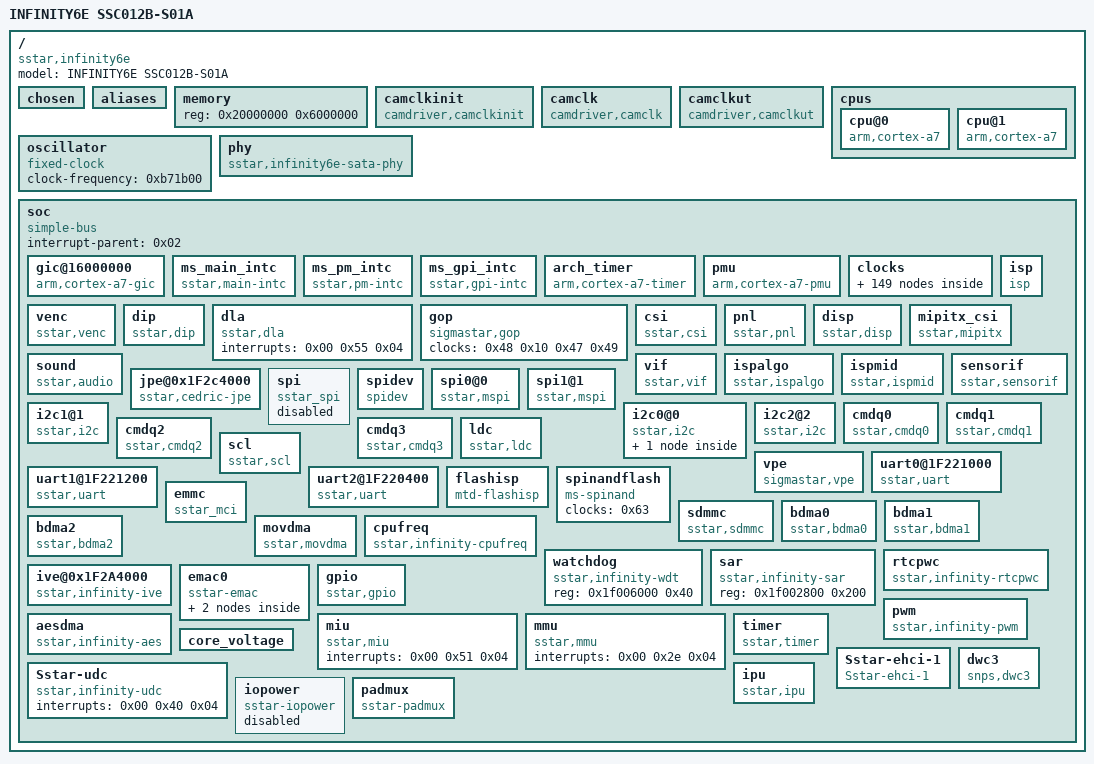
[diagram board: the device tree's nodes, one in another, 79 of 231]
/dts-v1/;

/ {
	#address-cells = <0x01>;
	#size-cells = <0x01>;
	model = "INFINITY6E SSC012B-S01A";
	compatible = "sstar,infinity6e";

	chosen {
		bootargs = "console=ttyS0,38400n8r androidboot.console=ttyS0 root=/dev/mtdblock0 init=/linuxrc LX_MEM=0x3ee0000 mma_heap=mma_heap_name0,miu=0,sz=0x2000000 mma_memblock_remove=1";
	};

	aliases {
		console = "/soc/uart0@1F221000";
		serial0 = "/soc/uart0@1F221000";
		serial1 = "/soc/uart1@1F221200";
		serial2 = "/soc/uart2@1F220400";
	};

	memory {
		device_type = "memory";
		reg = <0x20000000 0x6000000>;
	};

	camclkinit {
		compatible = "camdriver,camclkinit";
		status = "ok";
	};

	camclk {
		compatible = "camdriver,camclk";
		status = "ok";
	};

	camclkut {
		compatible = "camdriver,camclkut";
		status = "ok";
	};

	cpus {
		#address-cells = <0x01>;
		#size-cells = <0x00>;

		cpu@0 {
			device_type = "cpu";
			compatible = "arm,cortex-a7";
			clock-frequency = <0x3b9aca00>;
			clocks = <0x01>;
			reg = <0x00>;
			operating-points = <0x124f80 0xf4240 0x10c8e0 0xf4240 0xf4240 0xdbba0 0xdbba0 0xdbba0 0xc3500 0xcf850 0x927c0 0xcf850 0x61a80 0xcf850>;
		};

		cpu@1 {
			device_type = "cpu";
			compatible = "arm,cortex-a7";
			clock-frequency = <0x3b9aca00>;
			clocks = <0x01>;
			reg = <0x01>;
		};
	};

	oscillator {
		compatible = "fixed-clock";
		#clock-cells = <0x00>;
		clock-frequency = <0xb71b00>;
	};

	phy {
		compatible = "sstar,infinity6e-sata-phy";
		io_phy_addr = <0x1f000000>;
		banks = <0x1523 0x1524 0x1525>;
		reg = <0x1f2a4600 0x300>;
		#phy-cells = <0x00>;
		phy_type = "utmi";
		status = "ok";
		linux,phandle = <0x71>;
		phandle = <0x71>;
	};

	soc {
		compatible = "simple-bus";
		interrupt-parent = <0x02>;
		#address-cells = <0x01>;
		#size-cells = <0x01>;
		ranges;

		gic@16000000 {
			compatible = "arm,cortex-a7-gic";
			#interrupt-cells = <0x03>;
			#address-cells = <0x01>;
			#size-cells = <0x01>;
			interrupt-controller;
			interrupt-parent = <0x03>;
			reg = <0x16001000 0x1000 0x16002000 0x1000>;
			linux,phandle = <0x03>;
			phandle = <0x03>;
		};

		ms_main_intc {
			compatible = "sstar,main-intc";
			#interrupt-cells = <0x03>;
			#address-cells = <0x01>;
			#size-cells = <0x01>;
			interrupt-parent = <0x03>;
			interrupt-controller;
			linux,phandle = <0x02>;
			phandle = <0x02>;
		};

		ms_pm_intc {
			compatible = "sstar,pm-intc";
			#interrupt-cells = <0x01>;
			interrupt-parent = <0x02>;
			interrupt-controller;
			interrupts = <0x00 0x22 0x04>;
		};

		ms_gpi_intc {
			compatible = "sstar,gpi-intc";
			#interrupt-cells = <0x01>;
			interrupt-parent = <0x02>;
			interrupt-controller;
			interrupts = <0x00 0x58 0x04>;
			linux,phandle = <0x5d>;
			phandle = <0x5d>;
		};

		arch_timer {
			compatible = "arm,cortex-a7-timer\0arm,armv7-timer";
			interrupt-parent = <0x03>;
			interrupts = <0x01 0x0d 0x308 0x01 0x0e 0x308 0x01 0x0b 0x308 0x01 0x0a 0x308>;
			clock-frequency = <0x5b8d80>;
			always-on;
		};

		pmu {
			compatible = "arm,cortex-a7-pmu";
			interrupt-parent = <0x03>;
			interrupts = <0x00 0x0a 0x04 0x00 0x10 0x04 0x00 0x16 0x04 0x00 0x1c 0x04>;
		};

		clocks {
			#address-cells = <0x01>;
			#size-cells = <0x01>;
			ranges;

			CLK_VOID {
				#clock-cells = <0x00>;
				compatible = "fixed-clock";
				clock-frequency = <0x01>;
				linux,phandle = <0x17>;
				phandle = <0x17>;
			};

			CLK_utmi_480m {
				#clock-cells = <0x00>;
				compatible = "fixed-clock";
				clock-frequency = <0x1c9c3800>;
				linux,phandle = <0x35>;
				phandle = <0x35>;
			};

			CLK_mpll_432m {
				#clock-cells = <0x00>;
				compatible = "fixed-clock";
				clock-frequency = <0x19bfcc00>;
				linux,phandle = <0x14>;
				phandle = <0x14>;
			};

			CLK_upll_384m {
				#clock-cells = <0x00>;
				compatible = "fixed-clock";
				clock-frequency = <0x16e36000>;
				linux,phandle = <0x15>;
				phandle = <0x15>;
			};

			CLK_mpll_345m {
				#clock-cells = <0x00>;
				compatible = "fixed-clock";
				clock-frequency = <0x14904840>;
				linux,phandle = <0x3e>;
				phandle = <0x3e>;
			};

			CLK_upll_320m {
				#clock-cells = <0x00>;
				compatible = "fixed-clock";
				clock-frequency = <0x1312d000>;
				linux,phandle = <0x36>;
				phandle = <0x36>;
			};

			CLK_mpll_288m {
				#clock-cells = <0x00>;
				compatible = "fixed-clock";
				clock-frequency = <0x112a8800>;
				linux,phandle = <0x04>;
				phandle = <0x04>;
			};

			CLK_utmi_240m {
				#clock-cells = <0x00>;
				compatible = "fixed-clock";
				clock-frequency = <0xe4e1c00>;
				linux,phandle = <0x37>;
				phandle = <0x37>;
			};

			CLK_mpll_216m {
				#clock-cells = <0x00>;
				compatible = "fixed-clock";
				clock-frequency = <0xcdfe600>;
				linux,phandle = <0x05>;
				phandle = <0x05>;
			};

			CLK_utmi_192m {
				#clock-cells = <0x00>;
				compatible = "fixed-clock";
				clock-frequency = <0xb71b000>;
				linux,phandle = <0x08>;
				phandle = <0x08>;
			};

			CLK_mpll_172m {
				#clock-cells = <0x00>;
				compatible = "fixed-clock";
				clock-frequency = <0xa4cb800>;
				linux,phandle = <0x26>;
				phandle = <0x26>;
			};

			CLK_utmi_160m {
				#clock-cells = <0x00>;
				compatible = "fixed-clock";
				clock-frequency = <0x9896800>;
				linux,phandle = <0x09>;
				phandle = <0x09>;
			};

			CLK_mpll_123m {
				#clock-cells = <0x00>;
				compatible = "fixed-clock";
				clock-frequency = <0x75aef40>;
				linux,phandle = <0x06>;
				phandle = <0x06>;
			};

			CLK_mpll_86m {
				#clock-cells = <0x00>;
				compatible = "fixed-clock";
				clock-frequency = <0x5265c00>;
				linux,phandle = <0x07>;
				phandle = <0x07>;
			};

			CLK_mpll_288m_div2 {
				#clock-cells = <0x00>;
				compatible = "fixed-factor-clock";
				clocks = <0x04>;
				clock-div = <0x02>;
				clock-mult = <0x01>;
				linux,phandle = <0x27>;
				phandle = <0x27>;
			};

			CLK_mpll_288m_div4 {
				#clock-cells = <0x00>;
				compatible = "fixed-factor-clock";
				clocks = <0x04>;
				clock-div = <0x04>;
				clock-mult = <0x01>;
				linux,phandle = <0x23>;
				phandle = <0x23>;
			};

			CLK_mpll_288m_div8 {
				#clock-cells = <0x00>;
				compatible = "fixed-factor-clock";
				clocks = <0x04>;
				clock-div = <0x08>;
				clock-mult = <0x01>;
				linux,phandle = <0x20>;
				phandle = <0x20>;
			};

			CLK_mpll_216m_div2 {
				#clock-cells = <0x00>;
				compatible = "fixed-factor-clock";
				clocks = <0x05>;
				clock-div = <0x02>;
				clock-mult = <0x01>;
				linux,phandle = <0x1c>;
				phandle = <0x1c>;
			};

			CLK_mpll_216m_div4 {
				#clock-cells = <0x00>;
				compatible = "fixed-factor-clock";
				clocks = <0x05>;
				clock-div = <0x04>;
				clock-mult = <0x01>;
				linux,phandle = <0x22>;
				phandle = <0x22>;
			};

			CLK_mpll_216m_div8 {
				#clock-cells = <0x00>;
				compatible = "fixed-factor-clock";
				clocks = <0x05>;
				clock-div = <0x08>;
				clock-mult = <0x01>;
				linux,phandle = <0x1f>;
				phandle = <0x1f>;
			};

			CLK_mpll_123m_div2 {
				#clock-cells = <0x00>;
				compatible = "fixed-factor-clock";
				clocks = <0x06>;
				clock-div = <0x02>;
				clock-mult = <0x01>;
				linux,phandle = <0x2b>;
				phandle = <0x2b>;
			};

			CLK_mpll_86m_div2 {
				#clock-cells = <0x00>;
				compatible = "fixed-factor-clock";
				clocks = <0x07>;
				clock-div = <0x02>;
				clock-mult = <0x01>;
				linux,phandle = <0x2d>;
				phandle = <0x2d>;
			};

			CLK_mpll_86m_div4 {
				#clock-cells = <0x00>;
				compatible = "fixed-factor-clock";
				clocks = <0x07>;
				clock-div = <0x04>;
				clock-mult = <0x01>;
				linux,phandle = <0x2e>;
				phandle = <0x2e>;
			};

			CLK_mpll_86m_div16 {
				#clock-cells = <0x00>;
				compatible = "fixed-factor-clock";
				clocks = <0x07>;
				clock-div = <0x10>;
				clock-mult = <0x01>;
				linux,phandle = <0x2f>;
				phandle = <0x2f>;
			};

			CLK_utmi_192m_div4 {
				#clock-cells = <0x00>;
				compatible = "fixed-factor-clock";
				clocks = <0x08>;
				clock-div = <0x04>;
				clock-mult = <0x01>;
				linux,phandle = <0x2c>;
				phandle = <0x2c>;
			};

			CLK_utmi_160m_div4 {
				#clock-cells = <0x00>;
				compatible = "fixed-factor-clock";
				clocks = <0x09>;
				clock-div = <0x04>;
				clock-mult = <0x01>;
				linux,phandle = <0x38>;
				phandle = <0x38>;
			};

			CLK_utmi_160m_div5 {
				#clock-cells = <0x00>;
				compatible = "fixed-factor-clock";
				clocks = <0x09>;
				clock-div = <0x05>;
				clock-mult = <0x01>;
				linux,phandle = <0x3b>;
				phandle = <0x3b>;
			};

			CLK_utmi_160m_div8 {
				#clock-cells = <0x00>;
				compatible = "fixed-factor-clock";
				clocks = <0x09>;
				clock-div = <0x08>;
				clock-mult = <0x01>;
				linux,phandle = <0x3c>;
				phandle = <0x3c>;
			};

			CLK_xtali_12m {
				#clock-cells = <0x00>;
				compatible = "fixed-clock";
				clock-frequency = <0xb71b00>;
				linux,phandle = <0x0a>;
				phandle = <0x0a>;
			};

			CLK_xtali_12m_div2 {
				#clock-cells = <0x00>;
				compatible = "fixed-factor-clock";
				clocks = <0x0a>;
				clock-div = <0x02>;
				clock-mult = <0x01>;
				linux,phandle = <0x24>;
				phandle = <0x24>;
			};

			CLK_xtali_12m_div4 {
				#clock-cells = <0x00>;
				compatible = "fixed-factor-clock";
				clocks = <0x0a>;
				clock-div = <0x04>;
				clock-mult = <0x01>;
				linux,phandle = <0x25>;
				phandle = <0x25>;
			};

			CLK_xtali_12m_div8 {
				#clock-cells = <0x00>;
				compatible = "fixed-factor-clock";
				clocks = <0x0a>;
				clock-div = <0x08>;
				clock-mult = <0x01>;
				linux,phandle = <0x18>;
				phandle = <0x18>;
			};

			CLK_xtali_12m_div16 {
				#clock-cells = <0x00>;
				compatible = "fixed-factor-clock";
				clocks = <0x0a>;
				clock-div = <0x10>;
				clock-mult = <0x01>;
				linux,phandle = <0x19>;
				phandle = <0x19>;
			};

			CLK_xtali_12m_div40 {
				#clock-cells = <0x00>;
				compatible = "fixed-factor-clock";
				clocks = <0x0a>;
				clock-div = <0x28>;
				clock-mult = <0x01>;
				linux,phandle = <0x3d>;
				phandle = <0x3d>;
			};

			CLK_xtali_12m_div64 {
				#clock-cells = <0x00>;
				compatible = "fixed-factor-clock";
				clocks = <0x0a>;
				clock-div = <0x40>;
				clock-mult = <0x01>;
				linux,phandle = <0x1a>;
				phandle = <0x1a>;
			};

			CLK_xtali_12m_div128 {
				#clock-cells = <0x00>;
				compatible = "fixed-factor-clock";
				clocks = <0x0a>;
				clock-div = <0x80>;
				clock-mult = <0x01>;
				linux,phandle = <0x1b>;
				phandle = <0x1b>;
			};

			CLK_xtali_24m {
				#clock-cells = <0x00>;
				compatible = "fixed-clock";
				clock-frequency = <0x16e3600>;
				linux,phandle = <0x0b>;
				phandle = <0x0b>;
			};

			CLK_RTC_CLK_32K {
				#clock-cells = <0x00>;
				compatible = "fixed-clock";
				clock-frequency = <0x7d00>;
			};

			CLK_pm_riu_w_clk_in {
				#clock-cells = <0x00>;
				compatible = "fixed-clock";
				clock-frequency = <0x66ff300>;
			};

			CLK_miupll_clk {
				#clock-cells = <0x00>;
				compatible = "fixed-clock";
				clock-frequency = <0x17d78400>;
				linux,phandle = <0x16>;
				phandle = <0x16>;
			};

			CLK_ddrpll_clk {
				#clock-cells = <0x00>;
				compatible = "fixed-clock";
				clock-frequency = <0x7f22ff40>;
			};

			CLK_lpll_clk {
				#clock-cells = <0x00>;
				compatible = "fixed-clock";
				clock-frequency = <0x5f5e100>;
				linux,phandle = <0x30>;
				phandle = <0x30>;
			};

			CLK_ven_pll {
				#clock-cells = <0x00>;
				compatible = "sstar,complex-clock";
				clocks = <0x0b>;
				linux,phandle = <0x39>;
				phandle = <0x39>;
			};

			CLK_ven_pll_div6 {
				#clock-cells = <0x00>;
				compatible = "fixed-clock";
				clock-frequency = <0x632ea00>;
				linux,phandle = <0x21>;
				phandle = <0x21>;
			};

			CLK_lpll_div2 {
				#clock-cells = <0x00>;
				compatible = "fixed-clock";
				clock-frequency = <0x2faf080>;
				linux,phandle = <0x31>;
				phandle = <0x31>;
			};

			CLK_lpll_div4 {
				#clock-cells = <0x00>;
				compatible = "fixed-clock";
				clock-frequency = <0x17d7840>;
				linux,phandle = <0x32>;
				phandle = <0x32>;
			};

			CLK_lpll_div8 {
				#clock-cells = <0x00>;
				compatible = "fixed-clock";
				clock-frequency = <0xbebc20>;
				linux,phandle = <0x33>;
				phandle = <0x33>;
			};

			CLK_armpll_37p125m {
				#clock-cells = <0x00>;
				compatible = "fixed-clock";
				clock-frequency = <0x23c3460>;
				linux,phandle = <0x34>;
				phandle = <0x34>;
			};

			CLK_riu_w_clk_in {
				#clock-cells = <0x00>;
				compatible = "fixed-factor-clock";
				clocks = <0x0c>;
				clock-div = <0x01>;
				clock-mult = <0x01>;
			};

			CLK_riu_w_clk_top {
				#clock-cells = <0x00>;
				compatible = "fixed-factor-clock";
				clocks = <0x0c>;
				clock-div = <0x01>;
				clock-mult = <0x01>;
			};

			CLK_riu_w_clk_sc_gp {
				#clock-cells = <0x00>;
				compatible = "fixed-factor-clock";
				clocks = <0x0c>;
				clock-div = <0x01>;
				clock-mult = <0x01>;
			};

			CLK_riu_w_clk_vhe_gp {
				#clock-cells = <0x00>;
				compatible = "fixed-factor-clock";
				clocks = <0x0c>;
				clock-div = <0x01>;
				clock-mult = <0x01>;
			};

			CLK_riu_w_clk_hemcu_gp {
				#clock-cells = <0x00>;
				compatible = "fixed-factor-clock";
				clocks = <0x0c>;
				clock-div = <0x01>;
				clock-mult = <0x01>;
			};

			CLK_riu_w_clk_mipi_if_gp {
				#clock-cells = <0x00>;
				compatible = "fixed-factor-clock";
				clocks = <0x0c>;
				clock-div = <0x01>;
				clock-mult = <0x01>;
			};

			CLK_riu_w_clk_mcu_if_gp {
				#clock-cells = <0x00>;
				compatible = "fixed-factor-clock";
				clocks = <0x0c>;
				clock-div = <0x01>;
				clock-mult = <0x01>;
			};

			CLK_fuart0_synth_out {
				#clock-cells = <0x00>;
				compatible = "fixed-clock";
				clock-frequency = <0x19bfcc00>;
				linux,phandle = <0x28>;
				phandle = <0x28>;
			};

			CLK_miu_p {
				#clock-cells = <0x00>;
				compatible = "fixed-factor-clock";
				clocks = <0x0d>;
				clock-div = <0x01>;
				clock-mult = <0x01>;
				linux,phandle = <0x1e>;
				phandle = <0x1e>;
			};

			CLK_mspi0_p {
				#clock-cells = <0x00>;
				compatible = "fixed-factor-clock";
				clocks = <0x0e>;
				clock-div = <0x01>;
				clock-mult = <0x01>;
				linux,phandle = <0x29>;
				phandle = <0x29>;
			};

			CLK_mspi1_p {
				#clock-cells = <0x00>;
				compatible = "fixed-factor-clock";
				clocks = <0x0f>;
				clock-div = <0x01>;
				clock-mult = <0x01>;
				linux,phandle = <0x2a>;
				phandle = <0x2a>;
			};

			CLK_miu_vhe_gp_p {
				#clock-cells = <0x00>;
				compatible = "fixed-factor-clock";
				clocks = <0x0d>;
				clock-div = <0x01>;
				clock-mult = <0x01>;
			};

			CLK_miu_sc_gp_p {
				#clock-cells = <0x00>;
				compatible = "fixed-factor-clock";
				clocks = <0x0d>;
				clock-div = <0x01>;
				clock-mult = <0x01>;
			};

			CLK_mcu_p {
				#clock-cells = <0x00>;
				compatible = "fixed-factor-clock";
				clocks = <0x0c>;
				clock-div = <0x01>;
				clock-mult = <0x01>;
				linux,phandle = <0x1d>;
				phandle = <0x1d>;
			};

			CLK_fclk1_p {
				#clock-cells = <0x00>;
				compatible = "fixed-factor-clock";
				clocks = <0x10>;
				clock-div = <0x01>;
				clock-mult = <0x01>;
				linux,phandle = <0x12>;
				phandle = <0x12>;
			};

			CLK_sdio_p {
				#clock-cells = <0x00>;
				compatible = "fixed-factor-clock";
				clocks = <0x11>;
				clock-div = <0x01>;
				clock-mult = <0x01>;
			};

			CLK_tck_buf {
				#clock-cells = <0x00>;
				compatible = "fixed-clock";
				clock-frequency = <0x2faf080>;
			};

			CLK_eth_buf {
				#clock-cells = <0x00>;
				compatible = "fixed-clock";
				clock-frequency = <0x7735940>;
				linux,phandle = <0x3f>;
				phandle = <0x3f>;
			};

			CLK_rmii_buf {
				#clock-cells = <0x00>;
				compatible = "fixed-clock";
				clock-frequency = <0x7735940>;
				linux,phandle = <0x40>;
				phandle = <0x40>;
			};

			CLK_emac_testrx125_in_lan {
				#clock-cells = <0x00>;
				compatible = "fixed-clock";
				clock-frequency = <0x7735940>;
				linux,phandle = <0x3a>;
				phandle = <0x3a>;
			};

			CLK_gop0 {
				#clock-cells = <0x00>;
				compatible = "fixed-factor-clock";
				clocks = <0x12>;
				clock-div = <0x01>;
				clock-mult = <0x01>;
				linux,phandle = <0x48>;
				phandle = <0x48>;
			};

			CLK_rtc_32k {
				#clock-cells = <0x00>;
				compatible = "fixed-clock";
				clock-frequency = <0x8000>;
				linux,phandle = <0x41>;
				phandle = <0x41>;
			};

			CLK_fro {
				#clock-cells = <0x00>;
				compatible = "fixed-clock";
				clock-frequency = <0x2dc6c00>;
				linux,phandle = <0x13>;
				phandle = <0x13>;
			};

			CLK_fro_div2 {
				#clock-cells = <0x00>;
				compatible = "fixed-factor-clock";
				clocks = <0x13>;
				clock-div = <0x02>;
				clock-mult = <0x01>;
				linux,phandle = <0x43>;
				phandle = <0x43>;
			};

			CLK_fro_div8 {
				#clock-cells = <0x00>;
				compatible = "fixed-factor-clock";
				clocks = <0x13>;
				clock-div = <0x08>;
				clock-mult = <0x01>;
				linux,phandle = <0x42>;
				phandle = <0x42>;
			};

			CLK_fro_div16 {
				#clock-cells = <0x00>;
				compatible = "fixed-factor-clock";
				clocks = <0x13>;
				clock-div = <0x10>;
				clock-mult = <0x01>;
				linux,phandle = <0x44>;
				phandle = <0x44>;
			};

			CLK_cpupll_clk {
				#clock-cells = <0x00>;
				compatible = "sstar,complex-clock";
				clocks = <0x14>;
				linux,phandle = <0x01>;
				phandle = <0x01>;
			};

			CLK_utmi {
				#clock-cells = <0x00>;
				compatible = "fixed-clock";
				clock-frequency = <0x1c9c3800>;
				linux,phandle = <0x70>;
				phandle = <0x70>;
			};

			CLK_bach {
				#clock-cells = <0x00>;
				compatible = "sstar,composite-clock";
				clocks = <0x15>;
				reg = <0x1f2071b4 0x04>;
				gate-shift = <0x07>;
				linux,phandle = <0x56>;
				phandle = <0x56>;
			};

			CLK_miu {
				#clock-cells = <0x00>;
				compatible = "sstar,composite-clock";
				clocks = <0x05 0x16 0x17 0x17>;
				reg = <0x1f20705c 0x04>;
				mux-shift = <0x02>;
				mux-width = <0x02>;
				gate-shift = <0x00>;
				glitch-shift = <0x04>;
				auto-enable = <0x01>;
				linux,phandle = <0x0d>;
				phandle = <0x0d>;
			};

			CLK_miu_boot {
				#clock-cells = <0x00>;
				compatible = "sstar,composite-clock";
				clocks = <0x0a 0x0d>;
				reg = <0x1f20705c 0x04>;
				mux-shift = <0x02>;
				mux-width = <0x01>;
				gate-shift = <0x00>;
				auto-enable = <0x01>;
			};

			CLK_ddr_syn {
				#clock-cells = <0x00>;
				compatible = "sstar,composite-clock";
				clocks = <0x14 0x05 0x0a 0x17>;
				reg = <0x1f207064 0x04>;
				mux-shift = <0x02>;
				mux-width = <0x02>;
				gate-shift = <0x00>;
				auto-enable = <0x01>;
			};

			CLK_miu_rec {
				#clock-cells = <0x00>;
				compatible = "sstar,composite-clock";
				clocks = <0x18 0x19 0x1a 0x1b>;
				reg = <0x1f207060 0x04>;
				mux-shift = <0x02>;
				mux-width = <0x02>;
				gate-shift = <0x00>;
				auto-enable = <0x01>;
			};

			CLK_mcu {
				#clock-cells = <0x00>;
				compatible = "sstar,composite-clock";
				clocks = <0x05 0x14 0x15 0x1c>;
				reg = <0x1f207004 0x04>;
				mux-shift = <0x02>;
				mux-width = <0x02>;
				gate-shift = <0x00>;
				glitch-shift = <0x04>;
				auto-enable = <0x01>;
				linux,phandle = <0x0c>;
				phandle = <0x0c>;
			};

			CLK_riubrdg {
				#clock-cells = <0x00>;
				compatible = "sstar,composite-clock";
				clocks = <0x1d 0x17 0x17 0x17>;
				reg = <0x1f207004 0x04>;
				mux-shift = <0x0a>;
				mux-width = <0x02>;
				gate-shift = <0x08>;
				auto-enable = <0x01>;
			};

			CLK_bdma {
				#clock-cells = <0x00>;
				compatible = "sstar,composite-clock";
				clocks = <0x1e 0x17 0x17 0x17>;
				reg = <0x1f207180 0x04>;
				mux-shift = <0x02>;
				mux-width = <0x02>;
				gate-shift = <0x00>;
				auto-enable = <0x00>;
				linux,phandle = <0x63>;
				phandle = <0x63>;
			};

			CLK_spi_arb {
				#clock-cells = <0x00>;
				compatible = "sstar,composite-clock";
				clocks = <0x05 0x1c 0x07 0x1e>;
				reg = <0x1f2070c8 0x04>;
				mux-shift = <0x02>;
				mux-width = <0x02>;
				gate-shift = <0x00>;
				glitch-shift = <0x04>;
				auto-enable = <0x01>;
			};

			CLK_spi_flash {
				#clock-cells = <0x00>;
				compatible = "sstar,composite-clock";
				clocks = <0x0a 0x1f 0x20 0x21 0x22 0x23 0x07 0x1c>;
				reg = <0x1f2070e0 0x04>;
				mux-shift = <0x02>;
				mux-width = <0x03>;
				gate-shift = <0x00>;
				glitch-shift = <0x05>;
				auto-enable = <0x01>;
			};

			CLK_pwm {
				#clock-cells = <0x00>;
				compatible = "sstar,composite-clock";
				clocks = <0x0a 0x24 0x25 0x18 0x0b 0x07 0x17 0x17>;
				reg = <0x1f2070e0 0x04>;
				mux-shift = <0x0a>;
				mux-width = <0x03>;
				gate-shift = <0x08>;
				auto-enable = <0x00>;
				linux,phandle = <0x6e>;
				phandle = <0x6e>;
			};

			CLK_uart0 {
				#clock-cells = <0x00>;
				compatible = "sstar,composite-clock";
				clocks = <0x26 0x27 0x0a 0x17>;
				reg = <0x1f2070c4 0x04>;
				mux-shift = <0x02>;
				mux-width = <0x02>;
				gate-shift = <0x00>;
				auto-enable = <0x00>;
				linux,phandle = <0x60>;
				phandle = <0x60>;
			};

			CLK_uart1 {
				#clock-cells = <0x00>;
				compatible = "sstar,composite-clock";
				clocks = <0x26 0x27 0x0a 0x17>;
				reg = <0x1f2070c4 0x04>;
				mux-shift = <0x0a>;
				mux-width = <0x02>;
				gate-shift = <0x08>;
				auto-enable = <0x00>;
				linux,phandle = <0x61>;
				phandle = <0x61>;
			};

			CLK_fuart0_synth_in {
				#clock-cells = <0x00>;
				compatible = "sstar,composite-clock";
				clocks = <0x14 0x05 0x17 0x17>;
				reg = <0x1f2070d0 0x04>;
				mux-shift = <0x06>;
				mux-width = <0x02>;
				gate-shift = <0x04>;
				auto-enable = <0x00>;
			};

			CLK_fuart {
				#clock-cells = <0x00>;
				compatible = "sstar,composite-clock";
				clocks = <0x26 0x27 0x0a 0x28>;
				reg = <0x1f2070d0 0x04>;
				mux-shift = <0x02>;
				mux-width = <0x02>;
				gate-shift = <0x00>;
				auto-enable = <0x00>;
				linux,phandle = <0x62>;
				phandle = <0x62>;
			};

			CLK_mspi0 {
				#clock-cells = <0x00>;
				compatible = "sstar,composite-clock";
				clocks = <0x1c 0x22 0x0a 0x27>;
				reg = <0x1f2070cc 0x04>;
				mux-shift = <0x02>;
				mux-width = <0x02>;
				gate-shift = <0x00>;
				auto-enable = <0x00>;
				linux,phandle = <0x0e>;
				phandle = <0x0e>;
			};

			CLK_mspi1 {
				#clock-cells = <0x00>;
				compatible = "sstar,composite-clock";
				clocks = <0x1c 0x22 0x0a 0x27>;
				reg = <0x1f2070cc 0x04>;
				mux-shift = <0x0a>;
				mux-width = <0x02>;
				gate-shift = <0x08>;
				auto-enable = <0x00>;
				linux,phandle = <0x0f>;
				phandle = <0x0f>;
			};

			CLK_mspi {
				#clock-cells = <0x00>;
				compatible = "sstar,composite-clock";
				clocks = <0x29 0x2a>;
				reg = <0x1f2070cc 0x04>;
				mux-shift = <0x0e>;
				mux-width = <0x01>;
				gate-shift = <0x0c>;
				auto-enable = <0x00>;
				linux,phandle = <0x5b>;
				phandle = <0x5b>;
			};

			CLK_miic0 {
				#clock-cells = <0x00>;
				compatible = "sstar,composite-clock";
				clocks = <0x23 0x22 0x0a 0x17>;
				reg = <0x1f2070dc 0x04>;
				mux-shift = <0x02>;
				mux-width = <0x02>;
				gate-shift = <0x00>;
				auto-enable = <0x00>;
				linux,phandle = <0x5c>;
				phandle = <0x5c>;
			};

			CLK_miic1 {
				#clock-cells = <0x00>;
				compatible = "sstar,composite-clock";
				clocks = <0x23 0x22 0x0a 0x17>;
				reg = <0x1f2070dc 0x04>;
				mux-shift = <0x0a>;
				mux-width = <0x02>;
				gate-shift = <0x08>;
				auto-enable = <0x00>;
				linux,phandle = <0x5e>;
				phandle = <0x5e>;
			};

			CLK_miic2 {
				#clock-cells = <0x00>;
				compatible = "sstar,composite-clock";
				clocks = <0x23 0x22 0x0a 0x17>;
				reg = <0x1f2070dc 0x04>;
				mux-shift = <0x0e>;
				mux-width = <0x02>;
				gate-shift = <0x0c>;
				auto-enable = <0x00>;
				linux,phandle = <0x5f>;
				phandle = <0x5f>;
			};

			CLK_bist {
				#clock-cells = <0x00>;
				compatible = "sstar,composite-clock";
				clocks = <0x26 0x1c 0x22 0x0a>;
				reg = <0x1f207008 0x04>;
				mux-shift = <0x02>;
				mux-width = <0x02>;
				gate-shift = <0x00>;
				auto-enable = <0x00>;
			};

			CLK_pwr_ctl {
				#clock-cells = <0x00>;
				compatible = "sstar,composite-clock";
				clocks = <0x19 0x18 0x0a 0x17>;
				reg = <0x1f207010 0x04>;
				mux-shift = <0x02>;
				mux-width = <0x02>;
				gate-shift = <0x00>;
				auto-enable = <0x01>;
			};

			CLK_xtali {
				#clock-cells = <0x00>;
				compatible = "sstar,composite-clock";
				clocks = <0x0a 0x17 0x17 0x17>;
				reg = <0x1f207000 0x04>;
				mux-shift = <0x02>;
				mux-width = <0x02>;
				gate-shift = <0x00>;
				auto-enable = <0x01>;
			};

			CLK_live {
				#clock-cells = <0x00>;
				compatible = "sstar,composite-clock";
				clocks = <0x0a 0x17 0x17 0x17>;
				reg = <0x1f207000 0x04>;
				mux-shift = <0x0a>;
				mux-width = <0x02>;
				gate-shift = <0x08>;
				auto-enable = <0x01>;
			};

			CLK_sr00_mclk {
				#clock-cells = <0x00>;
				compatible = "sstar,composite-clock";
				clocks = <0x1f 0x23 0x2b 0x22 0x2c 0x2d 0x20 0x0b 0x2e 0x0a 0x2f 0x30 0x31 0x32 0x33 0x34>;
				reg = <0x1f207188 0x04>;
				mux-shift = <0x0a>;
				mux-width = <0x04>;
				gate-shift = <0x08>;
				auto-enable = <0x00>;
				linux,phandle = <0x57>;
				phandle = <0x57>;
			};

			CLK_sr01_mclk {
				#clock-cells = <0x00>;
				compatible = "sstar,composite-clock";
				clocks = <0x1f 0x23 0x2b 0x22 0x2c 0x2d 0x20 0x0b 0x2e 0x0a 0x2f 0x30 0x31 0x32 0x33 0x34>;
				reg = <0x1f207194 0x04>;
				mux-shift = <0x02>;
				mux-width = <0x04>;
				gate-shift = <0x00>;
				auto-enable = <0x00>;
				linux,phandle = <0x59>;
				phandle = <0x59>;
			};

			CLK_sr1_mclk {
				#clock-cells = <0x00>;
				compatible = "sstar,composite-clock";
				clocks = <0x1f 0x23 0x2b 0x22 0x2c 0x2d 0x20 0x0b 0x2e 0x0a 0x2f 0x30 0x31 0x32 0x33 0x34>;
				reg = <0x1f207194 0x04>;
				mux-shift = <0x0a>;
				mux-width = <0x04>;
				gate-shift = <0x08>;
				auto-enable = <0x00>;
				linux,phandle = <0x58>;
				phandle = <0x58>;
			};

			CLK_bist_pm {
				#clock-cells = <0x00>;
				compatible = "sstar,composite-clock";
				clocks = <0x1c 0x22 0x1f 0x0a>;
				reg = <0x1f207008 0x04>;
				mux-shift = <0x0a>;
				mux-width = <0x02>;
				gate-shift = <0x08>;
				auto-enable = <0x00>;
			};

			CLK_bist_ipu_gp {
				#clock-cells = <0x00>;
				compatible = "sstar,composite-clock";
				clocks = <0x04 0x05 0x26 0x1c 0x07 0x22 0x1f 0x0a>;
				reg = <0x1f207014 0x04>;
				mux-shift = <0x02>;
				mux-width = <0x03>;
				gate-shift = <0x00>;
				auto-enable = <0x01>;
			};

			CLK_ipu {
				#clock-cells = <0x00>;
				compatible = "sstar,composite-clock";
				clocks = <0x0a 0x35 0x14 0x15 0x36 0x37 0x05 0x06>;
				reg = <0x1f207140 0x04>;
				mux-shift = <0x02>;
				mux-width = <0x03>;
				gate-shift = <0x00>;
				auto-enable = <0x00>;
			};

			CLK_ipuff {
				#clock-cells = <0x00>;
				compatible = "sstar,composite-clock";
				clocks = <0x14 0x15 0x36 0x37>;
				reg = <0x1f207140 0x04>;
				mux-shift = <0x0a>;
				mux-width = <0x02>;
				gate-shift = <0x08>;
				auto-enable = <0x00>;
			};

			CLK_bist_usb30_gp {
				#clock-cells = <0x00>;
				compatible = "sstar,composite-clock";
				clocks = <0x26 0x1c 0x22 0x0a>;
				reg = <0x1f207014 0x04>;
				mux-shift = <0x0a>;
				mux-width = <0x02>;
				gate-shift = <0x08>;
				auto-enable = <0x00>;
			};

			CLK_csi_mac_lptx_top_i_m00 {
				#clock-cells = <0x00>;
				compatible = "sstar,composite-clock";
				clocks = <0x05 0x37 0x26 0x27 0x07 0x38 0x17 0x17>;
				reg = <0x1f207160 0x04>;
				mux-shift = <0x02>;
				mux-width = <0x03>;
				gate-shift = <0x00>;
				auto-enable = <0x00>;
				linux,phandle = <0x4b>;
				phandle = <0x4b>;
			};

			CLK_csi_mac_top_i_m00 {
				#clock-cells = <0x00>;
				compatible = "sstar,composite-clock";
				clocks = <0x05 0x37 0x26 0x27 0x07 0x38 0x17 0x17>;
				reg = <0x1f207160 0x04>;
				mux-shift = <0x0a>;
				mux-width = <0x03>;
				gate-shift = <0x08>;
				auto-enable = <0x00>;
				linux,phandle = <0x4c>;
				phandle = <0x4c>;
			};

			CLK_ns_top_i_m00 {
				#clock-cells = <0x00>;
				compatible = "sstar,composite-clock";
				clocks = <0x05 0x37 0x26 0x27 0x07 0x38 0x17 0x17>;
				reg = <0x1f207164 0x04>;
				mux-shift = <0x02>;
				mux-width = <0x03>;
				gate-shift = <0x00>;
				auto-enable = <0x00>;
				linux,phandle = <0x4d>;
				phandle = <0x4d>;
			};

			CLK_csi_mac_lptx_top_i_m01 {
				#clock-cells = <0x00>;
				compatible = "sstar,composite-clock";
				clocks = <0x05 0x37 0x26 0x27 0x07 0x38 0x17 0x17>;
				reg = <0x1f207164 0x04>;
				mux-shift = <0x0a>;
				mux-width = <0x03>;
				gate-shift = <0x08>;
				auto-enable = <0x00>;
				linux,phandle = <0x51>;
				phandle = <0x51>;
			};

			CLK_csi_mac_top_i_m01 {
				#clock-cells = <0x00>;
				compatible = "sstar,composite-clock";
				clocks = <0x05 0x37 0x26 0x27 0x07 0x38 0x17 0x17>;
				reg = <0x1f207168 0x04>;
				mux-shift = <0x02>;
				mux-width = <0x03>;
				gate-shift = <0x00>;
				auto-enable = <0x00>;
				linux,phandle = <0x52>;
				phandle = <0x52>;
			};

			CLK_ns_top_i_m01 {
				#clock-cells = <0x00>;
				compatible = "sstar,composite-clock";
				clocks = <0x05 0x37 0x26 0x27 0x07 0x38 0x17 0x17>;
				reg = <0x1f207168 0x04>;
				mux-shift = <0x0a>;
				mux-width = <0x03>;
				gate-shift = <0x08>;
				auto-enable = <0x00>;
				linux,phandle = <0x53>;
				phandle = <0x53>;
			};

			CLK_csi_mac_lptx_top_i_m1 {
				#clock-cells = <0x00>;
				compatible = "sstar,composite-clock";
				clocks = <0x05 0x37 0x26 0x27 0x07 0x38 0x17 0x17>;
				reg = <0x1f20716c 0x04>;
				mux-shift = <0x02>;
				mux-width = <0x03>;
				gate-shift = <0x00>;
				auto-enable = <0x00>;
				linux,phandle = <0x4e>;
				phandle = <0x4e>;
			};

			CLK_csi_mac_top_i_m1 {
				#clock-cells = <0x00>;
				compatible = "sstar,composite-clock";
				clocks = <0x05 0x37 0x26 0x27 0x07 0x38 0x17 0x17>;
				reg = <0x1f20716c 0x04>;
				mux-shift = <0x0a>;
				mux-width = <0x03>;
				gate-shift = <0x08>;
				auto-enable = <0x00>;
				linux,phandle = <0x4f>;
				phandle = <0x4f>;
			};

			CLK_ns_top_i_m1 {
				#clock-cells = <0x00>;
				compatible = "sstar,composite-clock";
				clocks = <0x05 0x37 0x26 0x27 0x07 0x38 0x17 0x17>;
				reg = <0x1f207170 0x04>;
				mux-shift = <0x02>;
				mux-width = <0x03>;
				gate-shift = <0x00>;
				auto-enable = <0x00>;
				linux,phandle = <0x50>;
				phandle = <0x50>;
			};

			CLK_mipi1_tx_csi {
				#clock-cells = <0x00>;
				compatible = "sstar,composite-clock";
				clocks = <0x30 0x09 0x27 0x1c 0x05 0x37 0x04 0x36>;
				reg = <0x1f207170 0x04>;
				mux-shift = <0x0a>;
				mux-width = <0x03>;
				gate-shift = <0x08>;
				auto-enable = <0x00>;
				linux,phandle = <0x55>;
				phandle = <0x55>;
			};

			CLK_bist_vhe_gp {
				#clock-cells = <0x00>;
				compatible = "sstar,composite-clock";
				clocks = <0x04 0x05 0x26 0x1c 0x07 0x22 0x1f 0x0a>;
				reg = <0x1f20700c 0x04>;
				mux-shift = <0x0a>;
				mux-width = <0x03>;
				gate-shift = <0x08>;
				auto-enable = <0x00>;
			};

			CLK_vhe {
				#clock-cells = <0x00>;
				compatible = "sstar,composite-clock";
				clocks = <0x39 0x35 0x14 0x15 0x36 0x04 0x08 0x06>;
				reg = <0x1f2071a0 0x04>;
				mux-shift = <0x02>;
				mux-width = <0x03>;
				gate-shift = <0x07>;
				auto-enable = <0x00>;
				linux,phandle = <0x45>;
				phandle = <0x45>;
			};

			CLK_mfe {
				#clock-cells = <0x00>;
				compatible = "sstar,composite-clock";
				clocks = <0x05 0x15 0x36 0x39>;
				reg = <0x1f2071a4 0x04>;
				mux-shift = <0x02>;
				mux-width = <0x02>;
				gate-shift = <0x00>;
				auto-enable = <0x00>;
				linux,phandle = <0x46>;
				phandle = <0x46>;
			};

			CLK_xtali_sc_gp {
				#clock-cells = <0x00>;
				compatible = "sstar,composite-clock";
				clocks = <0x0a 0x17 0x17 0x17>;
				reg = <0x1f207000 0x04>;
				mux-shift = <0x06>;
				mux-width = <0x02>;
				gate-shift = <0x04>;
				auto-enable = <0x01>;
			};

			CLK_bist_sc_gp {
				#clock-cells = <0x00>;
				compatible = "sstar,composite-clock";
				clocks = <0x04 0x05 0x26 0x1c 0x07 0x22 0x1f 0x0a>;
				reg = <0x1f20700c 0x04>;
				mux-shift = <0x02>;
				mux-width = <0x03>;
				gate-shift = <0x00>;
				auto-enable = <0x01>;
			};

			CLK_emac_ahb {
				#clock-cells = <0x00>;
				compatible = "sstar,composite-clock";
				clocks = <0x27 0x06 0x07 0x3a>;
				reg = <0x1f207108 0x04>;
				mux-shift = <0x02>;
				mux-width = <0x02>;
				gate-shift = <0x00>;
				auto-enable = <0x00>;
				linux,phandle = <0x68>;
				phandle = <0x68>;
			};

			CLK_jpe {
				#clock-cells = <0x00>;
				compatible = "sstar,composite-clock";
				clocks = <0x35 0x14 0x15 0x36 0x04 0x05 0x17 0x17>;
				reg = <0x1f2071a8 0x04>;
				mux-shift = <0x02>;
				mux-width = <0x03>;
				gate-shift = <0x00>;
				auto-enable = <0x00>;
				linux,phandle = <0x5a>;
				phandle = <0x5a>;
			};

			CLK_aesdma {
				#clock-cells = <0x00>;
				compatible = "sstar,composite-clock";
				clocks = <0x07 0x26 0x17 0x17>;
				reg = <0x1f207184 0x04>;
				mux-shift = <0x02>;
				mux-width = <0x02>;
				gate-shift = <0x00>;
				glitch-shift = <0x04>;
				auto-enable = <0x00>;
				linux,phandle = <0x6f>;
				phandle = <0x6f>;
			};

			CLK_sdio {
				#clock-cells = <0x00>;
				compatible = "sstar,composite-clock";
				clocks = <0x2c 0x2d 0x38 0x20 0x3b 0x3c 0x0a 0x3d>;
				reg = <0x1f207114 0x04>;
				mux-shift = <0x02>;
				mux-width = <0x03>;
				gate-shift = <0x00>;
				auto-enable = <0x00>;
				linux,phandle = <0x11>;
				phandle = <0x11>;
			};

			CLK_sd {
				#clock-cells = <0x00>;
				compatible = "sstar,composite-clock";
				clocks = <0x2c 0x2d 0x38 0x20 0x3b 0x3c 0x0a 0x3d>;
				reg = <0x1f20710c 0x04>;
				mux-shift = <0x02>;
				mux-width = <0x03>;
				gate-shift = <0x00>;
				auto-enable = <0x00>;
				linux,phandle = <0x64>;
				phandle = <0x64>;
			};

			CLK_ecc {
				#clock-cells = <0x00>;
				compatible = "sstar,composite-clock";
				clocks = <0x09 0x1c 0x22 0x0a>;
				reg = <0x1f207110 0x04>;
				mux-shift = <0x02>;
				mux-width = <0x02>;
				gate-shift = <0x00>;
				linux,phandle = <0x65>;
				phandle = <0x65>;
			};

			CLK_isp {
				#clock-cells = <0x00>;
				compatible = "sstar,composite-clock";
				clocks = <0x36 0x04 0x05 0x08 0x26 0x06 0x23 0x15>;
				reg = <0x1f207184 0x04>;
				mux-shift = <0x0a>;
				mux-width = <0x03>;
				gate-shift = <0x08>;
				auto-enable = <0x00>;
				linux,phandle = <0x4a>;
				phandle = <0x4a>;
			};

			CLK_fclk1 {
				#clock-cells = <0x00>;
				compatible = "sstar,composite-clock";
				clocks = <0x3e 0x14 0x15 0x36 0x04 0x37 0x26 0x06>;
				reg = <0x1f207190 0x04>;
				mux-shift = <0x02>;
				mux-width = <0x03>;
				gate-shift = <0x00>;
				auto-enable = <0x00>;
				linux,phandle = <0x10>;
				phandle = <0x10>;
			};

			CLK_odclk {
				#clock-cells = <0x00>;
				compatible = "sstar,composite-clock";
				clocks = <0x07 0x2d 0x2e 0x30>;
				reg = <0x1f207198 0x04>;
				mux-shift = <0x02>;
				mux-width = <0x02>;
				gate-shift = <0x00>;
				auto-enable = <0x00>;
				linux,phandle = <0x54>;
				phandle = <0x54>;
			};

			CLK_dip {
				#clock-cells = <0x00>;
				compatible = "sstar,composite-clock";
				clocks = <0x35 0x14 0x15 0x36 0x04 0x37 0x26 0x06>;
				reg = <0x1f207148 0x04>;
				mux-shift = <0x02>;
				mux-width = <0x03>;
				gate-shift = <0x00>;
				auto-enable = <0x00>;
				linux,phandle = <0x47>;
				phandle = <0x47>;
			};

			CLK_emac_tx {
				#clock-cells = <0x00>;
				compatible = "sstar,composite-clock";
				clocks = <0x3f 0x40>;
				reg = <0x1f22668c 0x04>;
				mux-shift = <0x02>;
				mux-width = <0x01>;
				gate-shift = <0x00>;
				linux,phandle = <0x69>;
				phandle = <0x69>;
			};

			CLK_emac_rx {
				#clock-cells = <0x00>;
				compatible = "sstar,composite-clock";
				clocks = <0x3f 0x40>;
				reg = <0x1f226688 0x04>;
				mux-shift = <0x02>;
				mux-width = <0x01>;
				gate-shift = <0x00>;
				linux,phandle = <0x6a>;
				phandle = <0x6a>;
			};

			CLK_emac_tx_ref {
				#clock-cells = <0x00>;
				compatible = "sstar,composite-clock";
				clocks = <0x40 0x17>;
				reg = <0x1f22668c 0x04>;
				mux-shift = <0x0a>;
				mux-width = <0x01>;
				gate-shift = <0x08>;
				linux,phandle = <0x6b>;
				phandle = <0x6b>;
			};

			CLK_emac_rx_ref {
				#clock-cells = <0x00>;
				compatible = "sstar,composite-clock";
				clocks = <0x40 0x17>;
				reg = <0x1f226688 0x04>;
				mux-shift = <0x0a>;
				mux-width = <0x01>;
				gate-shift = <0x08>;
				linux,phandle = <0x6c>;
				phandle = <0x6c>;
			};

			CLK_ive {
				#clock-cells = <0x00>;
				compatible = "sstar,composite-clock";
				clocks = <0x05 0x26 0x06 0x07 0x04 0x36 0x15 0x17>;
				reg = <0x1f2071a8 0x04>;
				mux-shift = <0x0a>;
				mux-width = <0x03>;
				gate-shift = <0x08>;
				auto-enable = <0x00>;
				linux,phandle = <0x67>;
				phandle = <0x67>;
			};

			CLK_ldcfeye {
				#clock-cells = <0x00>;
				compatible = "sstar,composite-clock";
				clocks = <0x35 0x14 0x15 0x36 0x04 0x05 0x07 0x17>;
				reg = <0x1f20714c 0x04>;
				mux-shift = <0x02>;
				mux-width = <0x03>;
				gate-shift = <0x00>;
				auto-enable = <0x00>;
				linux,phandle = <0x49>;
				phandle = <0x49>;
			};

			CLK_live_pm {
				#clock-cells = <0x00>;
				compatible = "sstar,composite-clock";
				clocks = <0x0a 0x41 0x17 0x17>;
				reg = <0x1f001cd0 0x04>;
				mux-shift = <0x00>;
				mux-width = <0x02>;
				auto-enable = <0x00>;
			};

			CLK_mcu_pm_p1 {
				#clock-cells = <0x00>;
				compatible = "sstar,composite-clock";
				clocks = <0x0a 0x42 0x41 0x43>;
				reg = <0x1f001c80 0x04>;
				mux-shift = <0x02>;
				mux-width = <0x02>;
				gate-shift = <0x00>;
				auto-enable = <0x01>;
			};

			CLK_spi_pm {
				#clock-cells = <0x00>;
				compatible = "sstar,composite-clock";
				clocks = <0x13 0x41 0x07 0x1c 0x0a 0x43 0x0b 0x22>;
				reg = <0x1f001c80 0x04>;
				mux-shift = <0x0a>;
				mux-width = <0x03>;
				gate-shift = <0x08>;
				glitch-shift = <0x0d>;
				auto-enable = <0x01>;
			};

			CLK_miic_pm {
				#clock-cells = <0x00>;
				compatible = "sstar,composite-clock";
				clocks = <0x07 0x0a 0x43 0x41>;
				reg = <0x1f001c98 0x04>;
				mux-shift = <0x0e>;
				mux-width = <0x02>;
				gate-shift = <0x0c>;
				auto-enable = <0x00>;
			};

			CLK_pm_sleep {
				#clock-cells = <0x00>;
				compatible = "sstar,composite-clock";
				clocks = <0x0a 0x41 0x43 0x17>;
				reg = <0x1f001c88 0x04>;
				mux-shift = <0x0a>;
				mux-width = <0x02>;
				auto-enable = <0x01>;
			};

			CLK_rtc {
				#clock-cells = <0x00>;
				compatible = "sstar,composite-clock";
				clocks = <0x0a 0x41 0x17 0x17>;
				reg = <0x1f001c88 0x04>;
				mux-shift = <0x02>;
				mux-width = <0x02>;
				gate-shift = <0x00>;
				auto-enable = <0x01>;
				linux,phandle = <0x66>;
				phandle = <0x66>;
			};

			CLK_sar {
				#clock-cells = <0x00>;
				compatible = "sstar,composite-clock";
				clocks = <0x0a 0x41 0x17 0x17>;
				reg = <0x1f001c88 0x04>;
				mux-shift = <0x07>;
				mux-width = <0x02>;
				gate-shift = <0x05>;
				auto-enable = <0x01>;
			};

			CLK_pir {
				#clock-cells = <0x00>;
				compatible = "sstar,composite-clock";
				clocks = <0x0a 0x44 0x42 0x43>;
				reg = <0x1f001c98 0x04>;
				mux-shift = <0x0a>;
				mux-width = <0x02>;
				gate-shift = <0x08>;
				auto-enable = <0x00>;
			};

			CLK_pm_uart {
				#clock-cells = <0x00>;
				compatible = "sstar,composite-clock";
				clocks = <0x0a 0x41 0x1c 0x07>;
				reg = <0x1f001c94 0x04>;
				mux-shift = <0x02>;
				mux-width = <0x02>;
				gate-shift = <0x00>;
				auto-enable = <0x01>;
			};
		};

		venc {
			compatible = "sstar,venc";
			reg = <0x1f345200 0x800 0x1f2c5200 0x100 0x1f203c00 0x100 0x1f207800 0x100>;
			reg-names = "vpu-bit\0venc-brige\0hw-uart0\0hw-uart1";
			interrupts = <0x00 0x35 0x04>;
			interrupt-parent = <0x02>;
			interrupt-names = "mhe-irq";
			clocks = <0x45 0x46>;
			clock-names = "CKG_venc";
			status = "ok";
		};

		dip {
			compatible = "sstar,dip";
			interrupts = <0x00 0x5f 0x04>;
			clocks = <0x47>;
			status = "ok";
		};

		dla {
			compatible = "sstar,dla";
			interrupts = <0x00 0x55 0x04>;
			status = "ok";
		};

		gop {
			compatible = "sigmastar,gop";
			clocks = <0x48 0x10 0x47 0x49>;
			status = "ok";
		};

		isp {
			compatible = "isp";
			io_phy_addr = <0x1f000000>;
			banks = <0x1302>;
			interrupts = <0x00 0x39 0x04>;
			clocks = <0x4a>;
			status = "ok";
			clock-frequency-index = <0x00>;
		};

		csi {
			compatible = "sstar,csi";
			io_phy_addr = <0x1f000000>;
			banks = <0x120b 0x120c 0x120d 0x1208 0x1209 0x120a 0x1202 0x1203 0x1204 0x1038 0x120e>;
			interrupts = <0x00 0x41 0x04>;
			clocks = <0x4b 0x4c 0x4d 0x4e 0x4f 0x50 0x51 0x52 0x53>;
			status = "ok";
			csi_sr0_lane_num = <0x04>;
			csi_sr1_lane_num = <0x04>;
			csi_sr2_lane_num = <0x02>;
			csi_sr0_lane_select = <0x02 0x04 0x03 0x01 0x00>;
			csi_sr1_lane_select = <0x00 0x00 0x00 0x00 0x00>;
			csi_sr2_lane_select = <0x00 0x00 0x00>;
			csi_sr0_lane_pn_swap = <0x01 0x01 0x01 0x01 0x01>;
			csi_sr1_lane_pn_swap = <0x00 0x00 0x00 0x00 0x00>;
			csi_sr2_lane_pn_swap = <0x00 0x00 0x00>;
		};

		pnl {
			compatible = "sstar,pnl";
			status = "ok";
			ttl-24bit-mode = <0x00>;
			ttl-16bit-mode = <0x01>;
			jtag-mode = <0x01>;
			clocks = <0x54>;
			clock-names = "CLK_odclk";
			interrupts = <0x00 0x5b 0x04>;
		};

		disp {
			compatible = "sstar,disp";
			status = "ok";
			clocks = <0x54>;
			clock-names = "CLK_odclk";
			interrupts = <0x00 0x5b 0x04 0x00 0x34 0x04 0x00 0x5a 0x04 0x00 0x31 0x04>;
		};

		mipitx_csi {
			compatible = "sstar,mipitx";
			status = "ok";
			clocks = <0x55>;
			clock-names = "CLK_mipi1_tx_csi";
			interrupts = <0x00 0x56 0x04>;
		};

		sound {
			compatible = "sstar,audio";
			interrupts = <0x00 0x4a 0x04>;
			playback-volume-level = <0x40>;
			capture-volume-level = <0x40>;
			micin-pregain-level = <0x00>;
			micin-gain-level = <0x03>;
			linein-gain-level = <0x02>;
			amp-gpio = <0x07 0x01>;
			clocks = <0x56>;
			digmic-padmux = <0x06>;
			i2s-trx-shared-padmux = <0x01>;
			i2s-tx-padmux = <0x00>;
			i2s-rx-padmux = <0x00>;
			i2smck-padmux = <0x01>;
			i2smod-padmux = <0x00>;
			keep-i2s-clk = <0x00>;
			i2s-rx-tdm-ws-pgm = <0x00>;
			i2s-rx-tdm-ws-width = <0x00>;
			i2s-rx-tdm-ch-swap = <0x00 0x00>;
			i2s-tx-tdm-ws-pgm = <0x00>;
			i2s-tx-tdm-ws-width = <0x00>;
			i2s-tx-tdm-ch-swap = <0x00 0x00>;
			i2s-tx-tdm-active-slot = <0x03>;
			status = "ok";
		};

		vif {
			compatible = "sstar,vif";
			status = "ok";
			reg = <0x1f260800 0x600 0x00 0x00 0x00 0x00 0x00 0x00 0x00 0x00 0x00 0x00 0x1f207800 0x200 0x1f226600 0x200 0x1f207000 0x200 0x1f000000 0x400000 0x1f203c00 0x200>;
			clocks = <0x57 0x58 0x59>;
			interrupts = <0x00 0x59 0x04>;
			vif_sr0_mclk_37p125 = <0x01>;
			vif_sr1_mclk_37p125 = <0x01>;
			vif_sr2_mclk_37p125 = <0x01>;
			vif_sr0_par_mode = <0x02>;
			vif_sr0_mipi_mode = <0x01>;
			vif_sr0_bt656_mode = <0x01>;
			vif_sr0_mclk_mode = <0x00>;
			vif_sr0_parallel_rst_mode = <0x00>;
			vif_sr0_parallel_pdn_mode = <0x00>;
			vif_sr0_mipi_rst_mode = <0x00>;
			vif_sr0_mipi_pdn_mode = <0x01>;
			vif_sr0_mipi_ctrl_mode = <0x01>;
			vif_sr1_par_mode = <0x00>;
			vif_sr1_mipi_mode = <0x01>;
			vif_sr1_bt656_mode = <0x00>;
			vif_sr1_mipi_ctrl_mode = <0x01>;
			vif_sr1_mclk_mode = <0x00>;
			vif_sr1_rst_mode = <0x00>;
			vif_sr2_mipi_mode = <0x00>;
			vif_sr2_mipi_ctrl_mode = <0x00>;
			vif_sr2_mclk_mode = <0x00>;
			vif_sr2_rst_mode = <0x00>;
		};

		ispalgo {
			compatible = "sstar,ispalgo";
			status = "ok";
		};

		ispmid {
			compatible = "sstar,ispmid";
			status = "ok";
		};

		sensorif {
			compatible = "sstar,sensorif";
			status = "ok";
			sensorif_grp0_i2c = <0x01>;
			sensorif_grp1_i2c = <0x02>;
			sensorif_grp2_i2c = <0x01>;
		};

		jpe@0x1F2c4000 {
			compatible = "sstar,cedric-jpe";
			reg = <0x1f2c4000 0x100>;
			interrupts = <0x00 0x3d 0x04>;
			clocks = <0x5a>;
			clock-names = "CKG_jpe";
			clk-select = <0x00>;
			status = "ok";
		};

		spi {
			compatible = "sstar_spi";
			io_phy_addr = <0x1f000000>;
			banks = <0x1110 0x1111 0x1038 0x103c>;
			interrupts = <0x00 0x46 0x04 0x00 0x47 0x04>;
			spi0_mode = <0x01>;
			spi1_mode = <0x03>;
			status = "disabled";
		};

		spidev {
			compatible = "spidev";
		};

		spi0@0 {
			compatible = "sstar,mspi";
			mspi-group = <0x00>;
			clocks = <0x0e 0x5b>;
			reg = <0x1f222000 0x200>;
			interrupts = <0x00 0x46 0x04>;
			use-dma = <0x01>;
			status = "ok";
		};

		spi1@1 {
			compatible = "sstar,mspi";
			mspi-group = <0x01>;
			clocks = <0x0f 0x5b>;
			reg = <0x1f222200 0x200>;
			interrupts = <0x00 0x47 0x04>;
			use-dma = <0x01>;
			status = "ok";
		};

		i2c0@0 {
			compatible = "sstar,i2c";
			reg = <0x1f223000 0x200 0x1f207800 0x200 0x1f207000 0x200>;
			#address-cells = <0x01>;
			#size-cells = <0x00>;
			clocks = <0x5c>;
			i2c-group = <0x00>;
			i2c-en-dma = <0x01>;
			status = "ok";
			interrupts = <0x00 0x44 0x04>;
			i2c-padmux = <0x03>;

			goodix_gt911@5D {
				compatible = "goodix,gt911";
				reg = <0x5d>;
				goodix_rst = <0x31>;
				goodix_int = <0x40>;
				interrupts-extended = <0x5d 0x05>;
				interrupt-names = "goodix_int";
			};
		};

		i2c1@1 {
			compatible = "sstar,i2c";
			reg = <0x1f223200 0x200 0x1f207800 0x200 0x1f207000 0x200>;
			#address-cells = <0x01>;
			#size-cells = <0x00>;
			clocks = <0x5e>;
			i2c-group = <0x01>;
			i2c-en-dma = <0x01>;
			i2c-padmux = <0x01>;
			interrupts = <0x00 0x45 0x04>;
			status = "ok";
		};

		i2c2@2 {
			compatible = "sstar,i2c";
			reg = <0x1f223400 0x200 0x1f207800 0x200 0x1f207000 0x200>;
			#address-cells = <0x01>;
			#size-cells = <0x00>;
			clocks = <0x5f>;
			i2c-group = <0x02>;
			i2c-en-dma = <0x01>;
			i2c-padmux = <0x04>;
			interrupts = <0x00 0x2c 0x04>;
			status = "ok";
		};

		cmdq0 {
			compatible = "sstar,cmdq0";
			clocks = <0x0c>;
			interrupts = <0x00 0x31 0x04>;
			status = "ok";
		};

		cmdq1 {
			compatible = "sstar,cmdq1";
			clocks = <0x0c>;
			interrupts = <0x00 0x31 0x04>;
			status = "ok";
		};

		cmdq2 {
			compatible = "sstar,cmdq2";
			clocks = <0x0c>;
			interrupts = <0x00 0x31 0x04>;
			status = "ok";
		};

		cmdq3 {
			compatible = "sstar,cmdq3";
			clocks = <0x0c>;
			interrupts = <0x00 0x31 0x04>;
			status = "ok";
		};

		ldc {
			compatible = "sstar,ldc";
			reg = <0x1f287800 0x100 0x1f287a00 0x100>;
			interrupts = <0x00 0x4b 0x04>;
			clocks = <0x49>;
			clock-names = "CLK_ldcfeye";
			clk-select = <0x01>;
			status = "ok";
		};

		scl {
			compatible = "sstar,scl";
			status = "ok";
		};

		vpe {
			compatible = "sigmastar,vpe";
			reg = <0x1f242000 0x100>;
			interrupts = <0x00 0x34 0x04 0x00 0x5a 0x04 0x00 0x5b 0x04 0x00 0x31 0x04>;
			clocks = <0x10 0x54>;
			clock-names = "CLK_fclk1\0CLK_fclk2\0CLK_odclk";
			clk-select = <0x02>;
			status = "ok";
		};

		uart0@1F221000 {
			compatible = "sstar,uart";
			reg = <0x1f221000 0x100>;
			interrupts = <0x00 0x42 0x04>;
			status = "ok";
			clocks = <0x60>;
		};

		uart1@1F221200 {
			compatible = "sstar,uart";
			reg = <0x1f221200 0x100 0x1f006a00 0x100>;
			interrupts = <0x00 0x43 0x04 0x00 0x24 0x04>;
			clocks = <0x61>;
			pm_uart = <0x00>;
			pad = <0x3b>;
			status = "ok";
		};

		uart2@1F220400 {
			compatible = "sstar,uart";
			reg = <0x1f220400 0x100 0x1f220600 0x100>;
			interrupts = <0x00 0x4f 0x04 0x00 0x50 0x04>;
			clocks = <0x62>;
			sctp_enable = <0x01>;
			dma = <0x01>;
			pad = <0x2e>;
			status = "ok";
		};

		flashisp {
			compatible = "mtd-flashisp";
			clocks = <0x63>;
			quadread = <0x00>;
			status = "ok";
		};

		spinandflash {
			compatible = "ms-spinand";
			clocks = <0x63>;
			status = "ok";
		};

		emmc {
			compatible = "sstar_mci";
			clocks = <0x64 0x65>;
			interrupts = <0x00 0x32 0x04>;
			bus-width = <0x04>;
			status = "ok";
		};

		sdmmc {
			compatible = "sstar,sdmmc";
			slotnum = <0x02>;
			revcdz = <0x00>;
			slot-ip-orders = <0x00 0x01 0x02>;
			slot-max-clks = <0x1312d00 0x1312d00 0x1312d00>;
			slot-intcdzs = <0x01 0x01 0x00>;
			slot-pwr-gpios = <0x1d 0x39 0xffff>;
			slot-pwr-off-delay = <0x1e 0x1e 0x1e>;
			interrupts-extended = <0x02 0x00 0x32 0x04 0x02 0x00 0x33 0x04 0x02 0x00 0x77 0x04 0x02 0x00 0x78 0x04>;
			interrupt-names = "mie0_irq\0mie1_irq\0cdz_slot0_irq\0cdz_slot1_irq";
			clocks = <0x64 0x11 0x17>;
			status = "ok";
			slot-fakecdzs = <0x00 0x00 0x00>;
			slot-pad-orders = <0x00 0x02 0x01>;
			slot-cdzs-gpios = <0x1e 0x2b 0xffff>;
			slot-sdio-use = <0x00 0x00 0x00>;
			slot-removable = <0x01 0x01 0x01>;
		};

		bdma0 {
			compatible = "sstar,bdma0";
			interrupts = <0x00 0x48 0x04>;
			clocks = <0x63>;
			status = "ok";
		};

		bdma1 {
			compatible = "sstar,bdma1";
			interrupts = <0x00 0x49 0x04>;
			clocks = <0x63>;
			status = "ok";
		};

		bdma2 {
			compatible = "sstar,bdma2";
			interrupts = <0x00 0x5d 0x04>;
			clocks = <0x63>;
			status = "ok";
		};

		movdma {
			compatible = "sstar,movdma";
			interrupts = <0x00 0x5c 0x04>;
			clocks = <0x0d>;
			status = "ok";
		};

		cpufreq {
			compatible = "sstar,infinity-cpufreq";
			status = "ok";
		};

		watchdog {
			compatible = "sstar,infinity-wdt";
			reg = <0x1f006000 0x40>;
			status = "ok";
		};

		sar {
			compatible = "sstar,infinity-sar";
			reg = <0x1f002800 0x200>;
			status = "ok";
		};

		rtcpwc {
			compatible = "sstar,infinity-rtcpwc";
			reg = <0x1f006800 0x200>;
			interrupts = <0x00 0x28 0x04>;
			clocks = <0x66>;
			status = "ok";
		};

		ive@0x1F2A4000 {
			compatible = "sstar,infinity-ive";
			reg = <0x1f2a4000 0x100 0x1f2a4200 0x100>;
			interrupts = <0x00 0x4d 0x04>;
			clocks = <0x67>;
			status = "ok";
		};

		emac0 {
			compatible = "sstar-emac";
			interrupts = <0x00 0x3a 0x04 0x00 0x75 0x04>;
			clocks = <0x68 0x69 0x6a 0x6b 0x6c>;
			reg = <0x1f2a2000 0x800 0x1f343c00 0x600 0x1f2a2800 0x600>;
			pad = <0x1f2079b8 0x01 0x01>;
			pad_led = <0x1f20798c 0x77 0x21>;
			phy-handle = <0x6d>;
			status = "ok";

			mdio-bus {

				ethernet-phy@0 {
					phy-mode = "mii";
					linux,phandle = <0x6d>;
					phandle = <0x6d>;
				};
			};
		};

		gpio {
			compatible = "sstar,gpio";
		};

		pwm {
			compatible = "sstar,infinity-pwm";
			reg = <0x1f203200 0x400>;
			npwm = <0x0b>;
			pm_group_base = <0x1f003400>;
			clocks = <0x6e>;
			interrupts = <0x00 0x54 0x01>;
			pad-ctrl = <0xffff 0xffff 0xffff 0xffff 0xffff 0xffff 0xffff 0xffff 0xffff 0xffff 0xffff>;
			status = "ok";
		};

		aesdma {
			compatible = "sstar,infinity-aes";
			interrupts = <0x00 0x37 0x04>;
			clocks = <0x6f>;
			status = "ok";
		};

		miu {
			compatible = "sstar,miu";
			interrupts = <0x00 0x51 0x04>;
			status = "ok";
		};

		mmu {
			compatible = "sstar,mmu";
			interrupts = <0x00 0x2e 0x04>;
			status = "ok";
		};

		timer {
			compatible = "sstar,timer";
			reg = <0x1f006040 0x40 0x1f006080 0x40 0x1f0060c0 0x40>;
			interrupts = <0x00 0x60 0x04 0x00 0x61 0x04 0x00 0x63 0x04>;
			status = "ok";
		};

		core_voltage {
			vid_width = <0x02>;
			vid_gpios = <0x0d 0x0e>;
			vid_voltages = <0x352 0x384 0x3b6 0x3e8>;
		};

		Sstar-ehci-1 {
			compatible = "Sstar-ehci-1";
			clocks = <0x70>;
			interrupts = <0x00 0x3f 0x04>;
			dpdm_swap = <0x00>;
			power-enable-pad = <0x6b>;
			status = "ok";
		};

		Sstar-udc {
			compatible = "sstar,infinity-udc";
			interrupts = <0x00 0x40 0x04>;
			status = "ok";
		};

		dwc3 {
			compatible = "snps,dwc3";
			reg = <0x1f344200 0xcfff>;
			clocks = <0x4d>;
			clock-names = "ss_clk";
			maximum-speed = "super-speed";
			interrupts = <0x00 0x38 0x04>;
			interrupt-names = "dwc_usb3";
			phy_type = "utmi_wide";
			phys = <0x71 0x71>;
			phy-names = "usb2-phy\0usb3-phy";
			snps,incr-burst-type-adjustment = <0x01 0x04 0x08 0x10>;
		};

		iopower {
			compatible = "sstar-iopower";
			reg = <0x1f002800 0x64>;
			status = "disabled";
			pm_sar_atop_vddp1 = <0x00>;
			pm_sar_atop_pmspi = <0x00>;
		};

		padmux {
			compatible = "sstar-padmux";
			schematic = <0x6b 0x47 0x80000 0x6c 0x00 0x80100 0x6d 0x53 0x80200 0x6e 0x59 0x80300 0x6f 0x5f 0x80400 0x70 0x65 0x80500 0x71 0x6b 0x80600 0x72 0x71 0x80700 0x0f 0x7f 0x80900 0x1d 0x00 0x20000 0x21 0x39 0x20002 0x22 0x39 0x20003 0x20 0x39 0x20004 0x1f 0x39 0x20005 0x24 0x39 0x20006 0x23 0x39 0x20007 0x1e 0x3a 0x20001 0x39 0x00 0x20100 0x27 0x3c 0x20102 0x28 0x3c 0x20103 0x26 0x3c 0x20104 0x25 0x3c 0x20105 0x2a 0x3c 0x20106 0x29 0x3c 0x20107 0x2b 0x3e 0x20101 0x2c 0x88 0x10000 0x2d 0x8d 0x10100 0x31 0x00 0x70033 0x7f 0xff 0x00>;
			status = "ok";
		};

		ipu {
			compatible = "sstar,ipu";
			operating-points = <0xdbba0 0xf4240 0xc3500 0xf4240 0x927c0 0xdbba0 0x7a120 0xdbba0 0x61a80 0xdbba0 0x493e0 0xcf850>;
			status = "ok";
		};
	};
};
